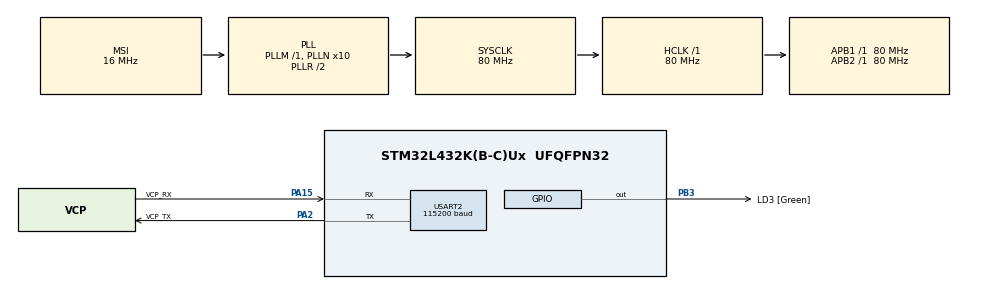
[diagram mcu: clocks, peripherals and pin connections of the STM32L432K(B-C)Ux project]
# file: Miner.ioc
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Mcu.Family=STM32L4
RCC.CortexFreq_Value=80000000
RTC.Alarm=RTC_ALARM_A
PA0.GPIO_Label=MCO [High speed clock in]
VP_RTC_VS_RTC_Activate.Mode=RTC_Enabled
PA15\ (JTDI).Signal=USART2_RX
PC15-OSC32_OUT\ (PC15).Mode=LSE-External-Oscillator
VP_RTC_VS_RTC_Alarm_A_Intern.Mode=Alarm A
RCC.SYSCLKSource=RCC_SYSCLKSOURCE_PLLCLK
ProjectManager.StackSize=0x400
PB3\ (JTDO-TRACESWO).Signal=GPIO_Output
PC14-OSC32_IN\ (PC14).Mode=LSE-External-Oscillator
PA14\ (JTCK-SWCLK).Signal=SYS_JTCK-SWCLK
PA15\ (JTDI).Mode=Asynchronous
RCC.HCLKFreq_Value=80000000
RCC.APB2TimFreq_Value=80000000
RCC.AHBFreq_Value=80000000
RCC.PREFETCH_ENABLE=1
RCC.HSE_VALUE=8000000
USART2.VirtualMode-Asynchronous=VM_ASYNC
RCC.RTCClockSelection=RCC_RTCCLKSOURCE_LSE
RCC.PLLMUL=RCC_PLLMUL_4
PA0.Mode=HSE-External-Clock-Source-for-LittleOrca
PA0.Signal=RCC_CK_IN
Mcu.Package=UFQFPN32
PA2.GPIO_Label=VCP_TX
VP_RTC_VS_RTC_Calendar.Mode=RTC_Calendar
RCC.APB1TimFreq_Value=80000000
PA13\ (JTMS-SWDIO).Signal=SYS_JTMS-SWDIO
RCC.MSIClockRange=RCC_MSIRANGE_8
RCC.HSI48_VALUE=48000000
RCC.PLLSAI1Q=RCC_PLLQ_DIV4
RCC.PLLSAI1N=12
RCC.MSI_VALUE=16000000
PA14\ (JTCK-SWCLK).Mode=Serial_Wire
RTC.AlarmMaskDateWeekDay=RTC_ALARMMASK_DATEWEEKDAY
PC15-OSC32_OUT\ (PC15).Signal=RCC_OSC32_OUT
PA14\ (JTCK-SWCLK).GPIO_Label=SWCLK
PB3\ (JTDO-TRACESWO).GPIO_Label=LD3 [Green]
NVIC.USART2_IRQn=true\:0\:0\:false\:false\:true\:true\:true
USART2.BaudRate=115200
RCC.HSI16_VALUE=16000000
RTC.AlarmMaskMinutes=RTC_ALARMMASK_MINUTES
ProjectManager.TargetToolchain=Makefile
RCC.USBFreq_Value=48000000
board=NUCLEO-L432KC
RCC.VCOOutputFreq_Value=160000000
RCC.APB2Freq_Value=80000000
PA13\ (JTMS-SWDIO).GPIO_Label=SWDIO
RCC.ADCFreq_Value=96000000
PA15\ (JTDI).GPIO_Label=VCP_RX
NVIC.RTC_Alarm_IRQn=true\:0\:0\:false\:false\:true\:true\:true
Mcu.Name=STM32L432K(B-C)Ux
RCC.EnableCSSLSE=true
PA2.Signal=USART2_TX
RTC.AlarmMaskHours=RTC_ALARMMASK_HOURS
PA13\ (JTMS-SWDIO).Mode=Serial_Wire
RCC.SYSCLKFreq_VALUE=80000000
PC14-OSC32_IN\ (PC14).Signal=RCC_OSC32_IN
ProjectManager.HeapSize=0x200
RCC.HSI_VALUE=16000000
NVIC.PriorityGroup=NVIC_PRIORITYGROUP_4
RCC.PLLN=10
PA2.Mode=Asynchronous
RCC.APB1Freq_Value=80000000

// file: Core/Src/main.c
/* USER CODE BEGIN Header */
/**
  ******************************************************************************
  * @file           : main.c
  * @brief          : Main program body
  ******************************************************************************
  * @attention
  *
  * <h2><center>&copy; Copyright (c) 2020 STMicroelectronics.
  * All rights reserved.</center></h2>
  *
  * This software component is licensed by ST under BSD 3-Clause license,
  * the "License"; You may not use this file except in compliance with the
  * License. You may obtain a copy of the License at:
  *                        opensource.org/licenses/BSD-3-Clause
  *
  ******************************************************************************
  */
/* USER CODE END Header */
#include "main.h"

/* USER CODE BEGIN Includes */
#include "common.h"
/* USER CODE END Includes */

RTC_HandleTypeDef hrtc;

UART_HandleTypeDef huart2;

/* USER CODE BEGIN PV */

volatile uint32_t hash_ctr=0;
volatile uint32_t stat_hashrate=0;
volatile uint32_t nonce_ctr=0;
uint64_t nonce=0;
uint64_t target=0x1000000000;
uint8_t blob[BLOBSIZE];
uint8_t job_buf[JOBSIZE];
struct flag_s flag;

/* USER CODE END PV */

void SystemClock_Config(void);
static void MX_GPIO_Init(void);
static void MX_USART2_UART_Init(void);
static void MX_RTC_Init(void);

/* USER CODE BEGIN 0 */

int _write (int file, char *buf, int nbytes)
{
	if ((file != STDOUT_FILENO) && (file != STDERR_FILENO))
	{
		errno = EBADF;
		return EOF;
	}
	HAL_UART_Transmit(&huart2, (uint8_t *)buf, nbytes, 0xFFFF);
	return nbytes;
}

void HAL_UART_RxCpltCallback(UART_HandleTypeDef *huart)
{
	flag.new_job = _TRUE;
	RECEIVE_JOB(job_buf, JOBSIZE);
}
/* USER CODE END 0 */

int main(void)
{

  /* MCU Configuration--------------------------------------------------------*/

  /* Reset of all peripherals, Initializes the Flash interface and the Systick. */
  HAL_Init();

  /* Configure the system clock */
  SystemClock_Config();

  /* Initialize all configured peripherals */
  MX_GPIO_Init();
  MX_USART2_UART_Init();
  MX_RTC_Init();
  /* USER CODE BEGIN 2 */
	RECEIVE_JOB(job_buf, JOBSIZE);
  /* USER CODE END 2 */

  /* Infinite loop */
  while (1)
  {

    /* USER CODE BEGIN 3 */
	if(flag.new_job)
	{
		write_job(job_buf, blob, &target);
		flag.new_job = _FALSE;
	}

	if(flag.print_stat)
	{
		printf("> %luH/s, shares: %lu, diff %lld\r\n", stat_hashrate, nonce_ctr, 0xFFFFFFFFFFFFFFFF / target);
		flag.print_stat = _FALSE;
	}

	mine(nonce, target, blob);
	hash_ctr += _LOOPS_K12;
	nonce += _LOOPS_K12;

	HAL_GPIO_TogglePin(LD3_GPIO_Port, LD3_Pin);
  }
  /* USER CODE END 3 */
}

void SystemClock_Config(void)
{
  RCC_OscInitTypeDef RCC_OscInitStruct = {0};
  RCC_ClkInitTypeDef RCC_ClkInitStruct = {0};
  RCC_PeriphCLKInitTypeDef PeriphClkInit = {0};

  /** Configure LSE Drive Capability
  */
  HAL_PWR_EnableBkUpAccess();
  __HAL_RCC_LSEDRIVE_CONFIG(RCC_LSEDRIVE_LOW);
  /** Initializes the RCC Oscillators according to the specified parameters
  * in the RCC_OscInitTypeDef structure.
  */
  RCC_OscInitStruct.OscillatorType = RCC_OSCILLATORTYPE_LSE|RCC_OSCILLATORTYPE_MSI;
  RCC_OscInitStruct.LSEState = RCC_LSE_ON;
  RCC_OscInitStruct.MSIState = RCC_MSI_ON;
  RCC_OscInitStruct.MSICalibrationValue = 0;
  RCC_OscInitStruct.MSIClockRange = RCC_MSIRANGE_8;
  RCC_OscInitStruct.PLL.PLLState = RCC_PLL_ON;
  RCC_OscInitStruct.PLL.PLLSource = RCC_PLLSOURCE_MSI;
  RCC_OscInitStruct.PLL.PLLM = 1;
  RCC_OscInitStruct.PLL.PLLN = 10;
  RCC_OscInitStruct.PLL.PLLP = RCC_PLLP_DIV7;
  RCC_OscInitStruct.PLL.PLLQ = RCC_PLLQ_DIV2;
  RCC_OscInitStruct.PLL.PLLR = RCC_PLLR_DIV2;
  if (HAL_RCC_OscConfig(&RCC_OscInitStruct) != HAL_OK)
  {
    Error_Handler();
  }
  /** Initializes the CPU, AHB and APB buses clocks
  */
  RCC_ClkInitStruct.ClockType = RCC_CLOCKTYPE_HCLK|RCC_CLOCKTYPE_SYSCLK
                              |RCC_CLOCKTYPE_PCLK1|RCC_CLOCKTYPE_PCLK2;
  RCC_ClkInitStruct.SYSCLKSource = RCC_SYSCLKSOURCE_PLLCLK;
  RCC_ClkInitStruct.AHBCLKDivider = RCC_SYSCLK_DIV1;
  RCC_ClkInitStruct.APB1CLKDivider = RCC_HCLK_DIV1;
  RCC_ClkInitStruct.APB2CLKDivider = RCC_HCLK_DIV1;

  if (HAL_RCC_ClockConfig(&RCC_ClkInitStruct, FLASH_LATENCY_4) != HAL_OK)
  {
    Error_Handler();
  }
  PeriphClkInit.PeriphClockSelection = RCC_PERIPHCLK_RTC|RCC_PERIPHCLK_USART2;
  PeriphClkInit.Usart2ClockSelection = RCC_USART2CLKSOURCE_PCLK1;
  PeriphClkInit.RTCClockSelection = RCC_RTCCLKSOURCE_LSE;
  if (HAL_RCCEx_PeriphCLKConfig(&PeriphClkInit) != HAL_OK)
  {
    Error_Handler();
  }
  /** Enables the Clock Security System
  */
  HAL_RCCEx_EnableLSECSS();
  /** Configure the main internal regulator output voltage
  */
  if (HAL_PWREx_ControlVoltageScaling(PWR_REGULATOR_VOLTAGE_SCALE1) != HAL_OK)
  {
    Error_Handler();
  }
  /** Enable MSI Auto calibration
  */
  HAL_RCCEx_EnableMSIPLLMode();
}

static void MX_RTC_Init(void)
{

  RTC_TimeTypeDef sTime = {0};
  RTC_DateTypeDef sDate = {0};
  RTC_AlarmTypeDef sAlarm = {0};

  /** Initialize RTC Only
  */
  hrtc.Instance = RTC;
  hrtc.Init.HourFormat = RTC_HOURFORMAT_24;
  hrtc.Init.AsynchPrediv = 127;
  hrtc.Init.SynchPrediv = 255;
  hrtc.Init.OutPut = RTC_OUTPUT_DISABLE;
  hrtc.Init.OutPutRemap = RTC_OUTPUT_REMAP_NONE;
  hrtc.Init.OutPutPolarity = RTC_OUTPUT_POLARITY_HIGH;
  hrtc.Init.OutPutType = RTC_OUTPUT_TYPE_OPENDRAIN;
  if (HAL_RTC_Init(&hrtc) != HAL_OK)
  {
    Error_Handler();
  }

  /** Initialize RTC and set the Time and Date
  */
  sTime.Hours = 0x0;
  sTime.Minutes = 0x0;
  sTime.Seconds = 0x0;
  sTime.DayLightSaving = RTC_DAYLIGHTSAVING_NONE;
  sTime.StoreOperation = RTC_STOREOPERATION_RESET;
  if (HAL_RTC_SetTime(&hrtc, &sTime, RTC_FORMAT_BCD) != HAL_OK)
  {
    Error_Handler();
  }
  sDate.WeekDay = RTC_WEEKDAY_MONDAY;
  sDate.Month = RTC_MONTH_JANUARY;
  sDate.Date = 0x1;
  sDate.Year = 0x0;

  if (HAL_RTC_SetDate(&hrtc, &sDate, RTC_FORMAT_BCD) != HAL_OK)
  {
    Error_Handler();
  }
  /** Enable the Alarm A
  */
  sAlarm.AlarmTime.Hours = 0x0;
  sAlarm.AlarmTime.Minutes = 0x0;
  sAlarm.AlarmTime.Seconds = 0x0;
  sAlarm.AlarmTime.SubSeconds = 0x0;
  sAlarm.AlarmTime.DayLightSaving = RTC_DAYLIGHTSAVING_NONE;
  sAlarm.AlarmTime.StoreOperation = RTC_STOREOPERATION_RESET;
  sAlarm.AlarmMask = RTC_ALARMMASK_DATEWEEKDAY|RTC_ALARMMASK_HOURS
                              |RTC_ALARMMASK_MINUTES;
  sAlarm.AlarmSubSecondMask = RTC_ALARMSUBSECONDMASK_ALL;
  sAlarm.AlarmDateWeekDaySel = RTC_ALARMDATEWEEKDAYSEL_DATE;
  sAlarm.AlarmDateWeekDay = 0x1;
  sAlarm.Alarm = RTC_ALARM_A;
  if (HAL_RTC_SetAlarm_IT(&hrtc, &sAlarm, RTC_FORMAT_BCD) != HAL_OK)
  {
    Error_Handler();
  }

}

static void MX_USART2_UART_Init(void)
{

  huart2.Instance = USART2;
  huart2.Init.BaudRate = 115200;
  huart2.Init.WordLength = UART_WORDLENGTH_8B;
  huart2.Init.StopBits = UART_STOPBITS_1;
  huart2.Init.Parity = UART_PARITY_NONE;
  huart2.Init.Mode = UART_MODE_TX_RX;
  huart2.Init.HwFlowCtl = UART_HWCONTROL_NONE;
  huart2.Init.OverSampling = UART_OVERSAMPLING_16;
  huart2.Init.OneBitSampling = UART_ONE_BIT_SAMPLE_DISABLE;
  huart2.AdvancedInit.AdvFeatureInit = UART_ADVFEATURE_NO_INIT;
  if (HAL_UART_Init(&huart2) != HAL_OK)
  {
    Error_Handler();
  }

}

static void MX_GPIO_Init(void)
{
  GPIO_InitTypeDef GPIO_InitStruct = {0};

  /* GPIO Ports Clock Enable */
  __HAL_RCC_GPIOC_CLK_ENABLE();
  __HAL_RCC_GPIOA_CLK_ENABLE();
  __HAL_RCC_GPIOB_CLK_ENABLE();
  __HAL_RCC_GPIOH_CLK_ENABLE();

  /*Configure GPIO pin Output Level */
  HAL_GPIO_WritePin(LD3_GPIO_Port, LD3_Pin, GPIO_PIN_RESET);

  /*Configure GPIO pins : PA1 PA3 PA4 PA5
                           PA6 PA7 PA8 PA9
                           PA10 PA11 PA12 */
  GPIO_InitStruct.Pin = GPIO_PIN_1|GPIO_PIN_3|GPIO_PIN_4|GPIO_PIN_5
                          |GPIO_PIN_6|GPIO_PIN_7|GPIO_PIN_8|GPIO_PIN_9
                          |GPIO_PIN_10|GPIO_PIN_11|GPIO_PIN_12;
  GPIO_InitStruct.Mode = GPIO_MODE_ANALOG;
  GPIO_InitStruct.Pull = GPIO_NOPULL;
  HAL_GPIO_Init(GPIOA, &GPIO_InitStruct);

  /*Configure GPIO pins : PB0 PB1 PB4 PB5
                           PB6 PB7 */
  GPIO_InitStruct.Pin = GPIO_PIN_0|GPIO_PIN_1|GPIO_PIN_4|GPIO_PIN_5
                          |GPIO_PIN_6|GPIO_PIN_7;
  GPIO_InitStruct.Mode = GPIO_MODE_ANALOG;
  GPIO_InitStruct.Pull = GPIO_NOPULL;
  HAL_GPIO_Init(GPIOB, &GPIO_InitStruct);

  /*Configure GPIO pin : LD3_Pin */
  GPIO_InitStruct.Pin = LD3_Pin;
  GPIO_InitStruct.Mode = GPIO_MODE_OUTPUT_PP;
  GPIO_InitStruct.Pull = GPIO_NOPULL;
  GPIO_InitStruct.Speed = GPIO_SPEED_FREQ_LOW;
  HAL_GPIO_Init(LD3_GPIO_Port, &GPIO_InitStruct);

  /*Configure GPIO pin : PH3 */
  GPIO_InitStruct.Pin = GPIO_PIN_3;
  GPIO_InitStruct.Mode = GPIO_MODE_ANALOG;
  GPIO_InitStruct.Pull = GPIO_NOPULL;
  HAL_GPIO_Init(GPIOH, &GPIO_InitStruct);

}

void Error_Handler(void)
{
}

#ifdef  USE_FULL_ASSERT
/**
  * @brief  Reports the name of the source file and the source line number
  *         where the assert_param error has occurred.
  * @param  file: pointer to the source file name
  * @param  line: assert_param error line source number
  * @retval None
  */
void assert_failed(uint8_t *file, uint32_t line)
{
  /* USER CODE BEGIN 6 */
  /* User can add his own implementation to report the file name and line number, */
	printf("Wrong parameters value: file %s on line %d\r\n", file, line);
  /* USER CODE END 6 */
}
#endif /* USE_FULL_ASSERT */

/************************ (C) COPYRIGHT STMicroelectronics *****END OF FILE****/
